# STM32H7R register map
File version: 1.3
CPU: CM7 r0p1, little endian, MPU, FPU, 4 interrupt priority bits
Registers are 32-bit, read-write, reset 0x0 unless marked. A register's access mark holds for its fields unless they carry their own. Offsets are from the block's base; [hi:lo] are bit positions; {n}, {i} and the like mark numbered series; 'fields as' and 'values as' point back to an identical list.

## OTG_HS (part 2 of 3) — OTG register block
Base 0x40040000
Same registers: OTG_FS 0x40080000
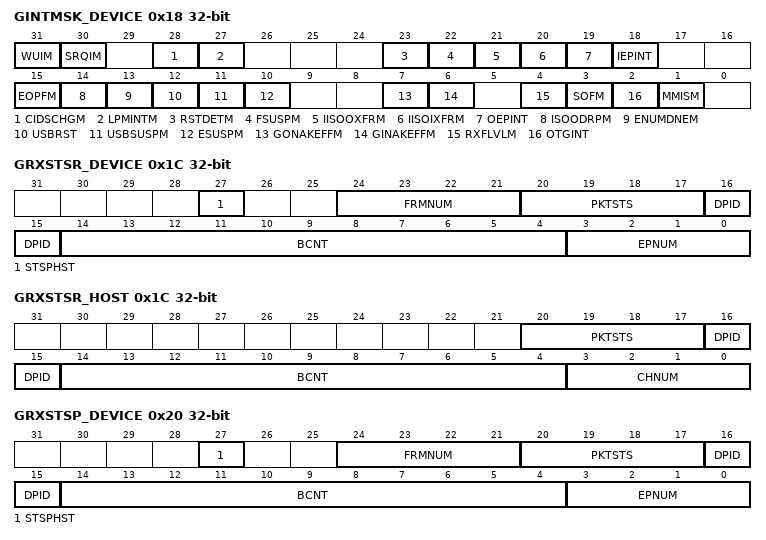
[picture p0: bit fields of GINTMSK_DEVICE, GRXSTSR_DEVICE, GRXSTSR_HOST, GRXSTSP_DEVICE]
0x18 GINTMSK_DEVICE (alternate view of GINTMSK_HOST) — OTG interrupt mask register
  [31] WUIM — Resume/remote wakeup detected interrupt mask
  [30] SRQIM — Session request/new session detected interrupt mask
  [28] CIDSCHGM — Connector ID status change mask
  [27] LPMINTM — LPM interrupt mask
  [23] RSTDETM — Reset detected interrupt mask
  [22] FSUSPM — Data fetch suspended mask
  [21] IISOOXFRM — Incomplete isochronous OUT transfer mask
  [20] IISOIXFRM — Incomplete isochronous IN transfer mask
  [19] OEPINT — OUT endpoints interrupt mask
  [18] IEPINT — IN endpoints interrupt mask
  [15] EOPFM — End of periodic frame interrupt mask
  [14] ISOODRPM — Isochronous OUT packet dropped interrupt mask
  [13] ENUMDNEM — Enumeration done mask
  [12] USBRST — USB reset mask
  [11] USBSUSPM — USB suspend mask
  [10] ESUSPM — Early suspend mask
  [7] GONAKEFFM — Global OUT NAK effective mask
  [6] GINAKEFFM — Global non-periodic IN NAK effective mask
  [4] RXFLVLM — Receive FIFO non-empty mask
  [3] SOFM — Start of frame mask
  [2] OTGINT — OTG interrupt mask
  [1] MMISM — Mode mismatch interrupt mask
0x1C GRXSTSR_DEVICE ro — OTG receive status debug read register
  [27] STSPHST — Status phase start Indicates the start of the status phase for a control write transfer. This bit is set along with the OUT transfer completed PKTSTS pattern.
  [24:21] FRMNUM — Frame number This is the least significant 4 bits of the frame number in which the packet is received on the USB. This field is supported only when isochronous OUT endpoints are supported.
  [20:17] PKTSTS — Packet status Indicates the status of the received packet Others: Reserved
  [16:15] DPID — Data PID Indicates the data PID of the received OUT data packet
  [14:4] BCNT — Byte count Indicates the byte count of the received data packet.
  [3:0] EPNUM — Endpoint number Indicates the endpoint number to which the current received packet belongs.
0x1C GRXSTSR_HOST ro (alternate view of GRXSTSR_DEVICE) — OTG receive status debug read register
  [20:17] PKTSTS — Packet status Indicates the status of the received packet Others: Reserved
  [16:15] DPID — Data PID Indicates the data PID of the received packet
  [14:4] BCNT — Byte count Indicates the byte count of the received IN data packet.
  [3:0] CHNUM — Channel number Indicates the channel number to which the current received packet belongs.
0x20 GRXSTSP_DEVICE ro — OTG status read and pop registers
  fields as GRXSTSR_DEVICE
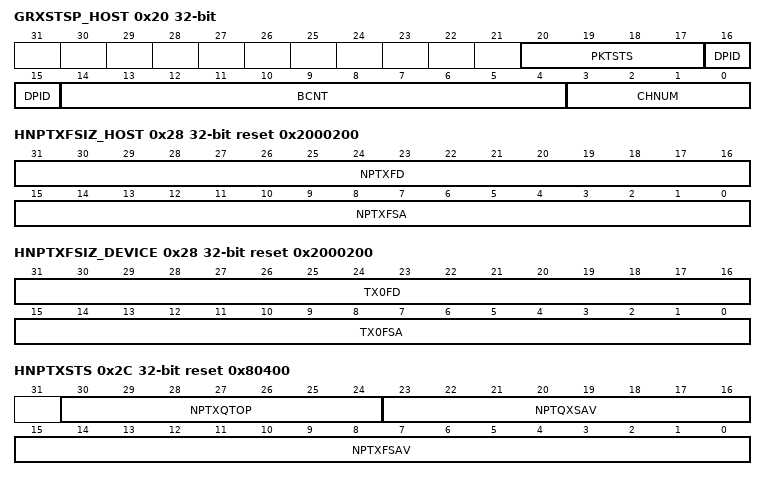
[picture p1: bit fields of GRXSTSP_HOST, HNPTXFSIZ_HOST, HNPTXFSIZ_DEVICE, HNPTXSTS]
0x20 GRXSTSP_HOST ro (alternate view of GRXSTSP_DEVICE) — OTG status read and pop registers
  fields as GRXSTSR_HOST
0x24 GRXFSIZ reset 0x400 — OTG receive FIFO size register
  [15:0] RXFD — Rx FIFO depth This value is in terms of 32-bit words. Maximum value is 1024 Programmed values must respect the available FIFO memory allocation and must not exceed the power-on value.
0x28 HNPTXFSIZ_HOST reset 0x2000200 — OTG host non-periodic transmit FIFO size register [alternate]
  [31:16] NPTXFD — Non-periodic Tx FIFO depth This value is in terms of 32-bit words. Minimum value is 16 Programmed values must respect the available FIFO memory allocation and must not exceed the power-on value.
  [15:0] NPTXFSA — Non-periodic transmit RAM start address This field configures the memory start address for non-periodic transmit FIFO RAM.
0x28 HNPTXFSIZ_DEVICE reset 0x2000200 (alternate view of HNPTXFSIZ_HOST) — OTG host non-periodic transmit FIFO size register [alternate]
  [31:16] TX0FD — Endpoint 0 Tx FIFO depth This value is in terms of 32-bit words. Minimum value is 16 Programmed values must respect the available FIFO memory allocation and must not exceed the power-on value.
  [15:0] TX0FSA — Endpoint 0 transmit RAM start address This field configures the memory start address for the endpoint 0 transmit FIFO RAM.
0x2C HNPTXSTS ro reset 0x80400 — OTG non-periodic transmit FIFO/queue status register
  [30:24] NPTXQTOP — Top of the non-periodic transmit request queue Entry in the non-periodic Tx request queue that is currently being processed by the MAC. Bits 30:27: Channel/endpoint number Bits 26:25: XXXX00X: IN/OUT token XXXX01X: Zero-length transmit packet (device IN/host OUT) XXXX11X: Channel halt command Bit 24: Terminate (last entry for selected channel/endpoint)
  [23:16] NPTQXSAV — Non-periodic transmit request queue space available Indicates the amount of free space available in the non-periodic transmit request queue. This queue holds both IN and OUT requests. n: n locations available (0 UNDER OR EQUAL n UNDER OR EQUAL 8) Others: Reserved
  [15:0] NPTXFSAV — Non-periodic Tx FIFO space available Indicates the amount of free space available in the non-periodic Tx FIFO. Values are in terms of 32-bit words. n: n words available (where 0 UNDER OR EQUAL n UNDER OR EQUAL 512) Others: Reserved
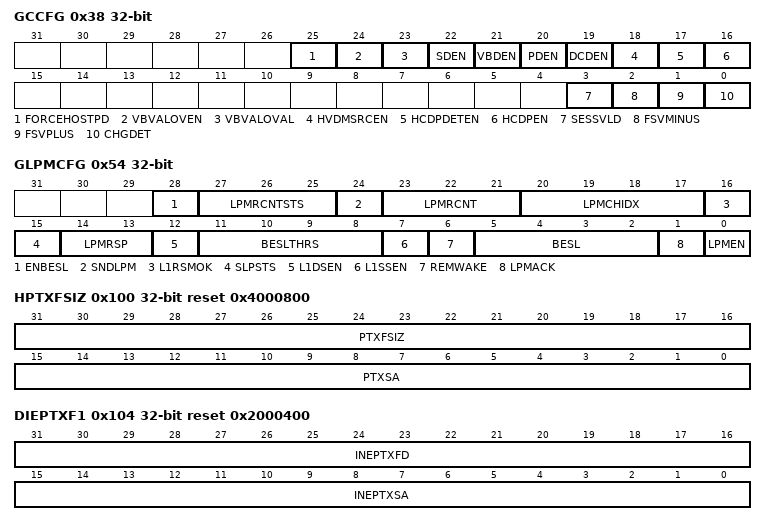
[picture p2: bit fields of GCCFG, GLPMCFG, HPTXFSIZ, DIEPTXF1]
0x38 GCCFG access per field (reset mask 0xFFFF0000) — OTG general core configuration register
  [25] FORCEHOSTPD rw — Force host mode pull-downs If the ID pin functions are enabled, the host mode pull-downs on DP and DM activate automatically. However, whenever that is not the case, yet host mode is required, this bit must be used to force the pull-downs active.
  [24] VBVALOVEN rw — Enables a software override of the VBUS B-session detection.
  [23] VBVALOVAL rw — Software override value of the VBUS B-session detection
  [22] SDEN rw — Secondary detection enable
  [21] VBDEN rw — VBUS detection enable Enables VBUS Sensing Comparators in order to detect VBUS presence and/or perform OTG operation.
  [20] PDEN rw — Primary detection enable
  [19] DCDEN rw — Data Contact Detection enable
  [18] HVDMSRCEN rw — Host CDP port Voltage source enable on DM
  [17] HCDPDETEN rw — Host CDP port voltage detector enable on DP
  [16] HCDPEN rw — Host CDP behavior enable
  [3] SESSVLD ro — VBUS session indicator Indicates if VBUS is above VBUS session threshold.
  [2] FSVMINUS ro — Single-Ended DM indicator This bit gives the voltage level on DM (also result of the comparison with V<sub>LGC</sub> threshold as defined in BC v1.2 standard).
  [1] FSVPLUS ro — Single-Ended DP indicator This bit gives the voltage level on DP (also result of the comparison with V<sub>LGC</sub> threshold as defined in BC v1.2 standard).
  [0] CHGDET ro — Charger detection, result of the current mode (primary or secondary).
0x3C CID reset 0x5000 — OTG core ID register
  [31:0] PRODUCT_ID — Product ID field Application-programmable ID field.
0x54 GLPMCFG access per field — OTG core LPM configuration register
  [28] ENBESL rw — Enable best effort service latency This bit enables the BESL feature as defined in the LPM errata: USB 2.0 Link Power Management Addendum Engineering Change Notice to the USB 2.0 specification, July 16, 2007 Errata for USB 2.0 ECN: Link Power Management (LPM) - 7/2007 Note: Only the updated behavior (described in LPM Errata) is considered in this document and so the ENBESL bit should be set to '1' by application SW.
  [27:25] LPMRCNTSTS ro — LPM retry count status Number of LPM host retries still remaining to be transmitted for the current LPM sequence. Note: Accessible only in host mode.
  [24] SNDLPM rw — Send LPM transaction When the application software sets this bit, an LPM transaction containing two tokens, EXT and LPM is sent. The hardware clears this bit once a valid response (STALL, NYET, or ACK) is received from the device or the core has finished transmitting the programmed number of LPM retries. Note: This bit must be set only when the host is connected to a local port. Note: Accessible only in host mode.
  [23:21] LPMRCNT rw — LPM retry count When the device gives an ERROR response, this is the number of additional LPM retries that the host performs until a valid device response (STALL, NYET, or ACK) is received. Note: Accessible only in host mode.
  [20:17] LPMCHIDX rw — LPM Channel Index The channel number on which the LPM transaction has to be applied while sending an LPM transaction to the local device. Based on the LPM channel index, the core automatically inserts the device address and endpoint number programmed in the corresponding channel into the LPM transaction. Note: Accessible only in host mode.
  [16] L1RSMOK ro — Sleep state resume OK
  [15] SLPSTS ro — Port sleep status Device mode: This bit is set as long as a Sleep condition is present on the USB bus. The core enters the Sleep state when an ACK response is sent to an LPM transaction and the T<sub>L1TokenRetry</sub> timer has expired. To stop the PHY clock, the application must set the STPPCLK bit in OTG_PCGCCTL, which asserts the PHY suspend input signal. The application must rely on SLPSTS and not ACK in LPMRSP to confirm transition into sleep. The core comes out of sleep: When there is any activity on the USB linestate When the application writes to the RWUSIG bit in OTG_DCTL or when the application resets or soft-disconnects the device. Host mode: The host transitions to Sleep (L1) state as a side-effect of a successful LPM transaction by the core to the local port with ACK response from the device. The read value of this bit reflects the current Sleep status of the port. The core clears this bit after: The core detects a remote L1 wakeup signal, The application sets the PRST bit or the PRES bit in the OTG_HPRT register, or The application sets the L1Resume/ remote wakeup detected interrupt bit or disconnect detected interrupt bit in the core interrupt register (WKUPINT or DISCINT bit in OTG_GINTSTS, respectively).
  [14:13] LPMRSP ro — LPM response Device mode: The response of the core to LPM transaction received is reflected in these two bits. Host mode: Handshake response received from local device for LPM transaction
  [12] L1DSEN rw — L1 deep sleep enable Enables suspending the PHY in L1 Sleep mode. For maximum power saving during L1 Sleep mode, this bit should be set to '1' by application SW in all the cases.
  [11:8] BESLTHRS rw — BESL threshold Device mode
  [7] L1SSEN rw — L1 Shallow Sleep enable Enables suspending the PHY in L1 Sleep mode. For maximum power saving during L1 Sleep mode, this bit should be set to '1' by application SW in all the cases.
  [6] REMWAKE rw — bRemoteWake value Host mode: The value of remote wake up to be sent in the wIndex field of LPM transaction. Device mode (read-only): This field is updated with the received LPM token bRemoteWake bmAttribute when an ACK, NYET, or STALL response is sent to an LPM transaction.
  [5:2] BESL rw — Best effort service latency Host mode
  [1] LPMACK rw — LPM token acknowledge enable Handshake response to LPM token preprogrammed by device application software. Even though ACK is preprogrammed, the core device responds with ACK only on successful LPM transaction. The LPM transaction is successful if: No PID/CRC5 errors in either EXT token or LPM token (else ERROR) Valid bLinkState = 0001B (L1) received in LPM transaction (else STALL) No data pending in transmit queue (else NYET). The preprogrammed software bit is over-ridden for response to LPM token when: The received bLinkState is not L1 (STALL response), or An error is detected in either of the LPM token packets because of corruption (ERROR response). Note: Accessible only in device mode.
  [0] LPMEN rw — LPM support enable The application uses this bit to control the OTG_HS core LPM capabilities. If the core operates as a non-LPM-capable host, it cannot request the connected device or hub to activate LPM mode. If the core operates as a non-LPM-capable device, it cannot respond to any LPM transactions.
0x100 HPTXFSIZ reset 0x4000800 — OTG host periodic transmit FIFO size register
  [31:16] PTXFSIZ — Host periodic Tx FIFO depth This value is in terms of 32-bit words. Minimum value is 16
  [15:0] PTXSA — Host periodic Tx FIFO start address This field configures the memory start address for periodic transmit FIFO RAM.
0x104 DIEPTXF1 reset 0x2000400 — OTG device IN endpoint transmit FIFO 1 size register
  [31:16] INEPTXFD — IN endpoint Tx FIFO depth This value is in terms of 32-bit words. Minimum value is 16
  [15:0] INEPTXSA — IN endpoint FIFOx transmit RAM start address This field contains the memory start address for IN endpoint transmit FIFOx. The address must be aligned with a 32-bit memory location.
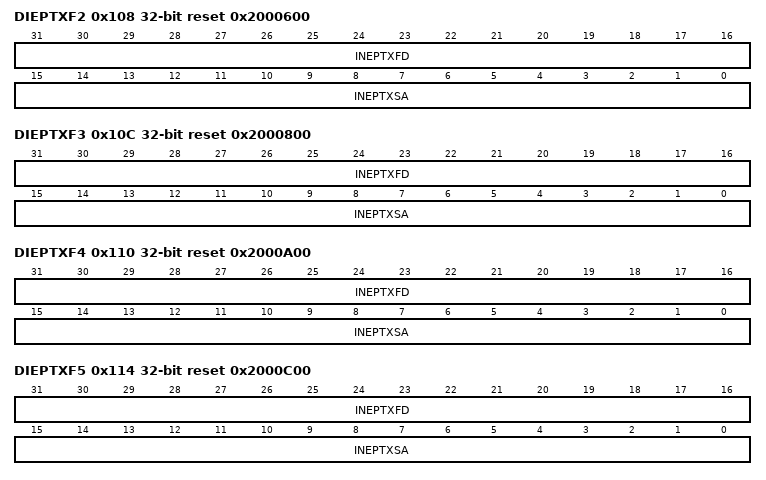
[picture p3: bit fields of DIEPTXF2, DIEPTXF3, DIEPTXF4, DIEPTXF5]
0x108 DIEPTXF2 reset 0x2000600 — OTG device IN endpoint transmit FIFO 2 size register
  fields as DIEPTXF1
0x10C DIEPTXF3 reset 0x2000800 — OTG device IN endpoint transmit FIFO 3 size register
  fields as DIEPTXF1
0x110 DIEPTXF4 reset 0x2000A00 — OTG device IN endpoint transmit FIFO 4 size register
  fields as DIEPTXF1
0x114 DIEPTXF5 reset 0x2000C00 — OTG device IN endpoint transmit FIFO 5 size register
  fields as DIEPTXF1
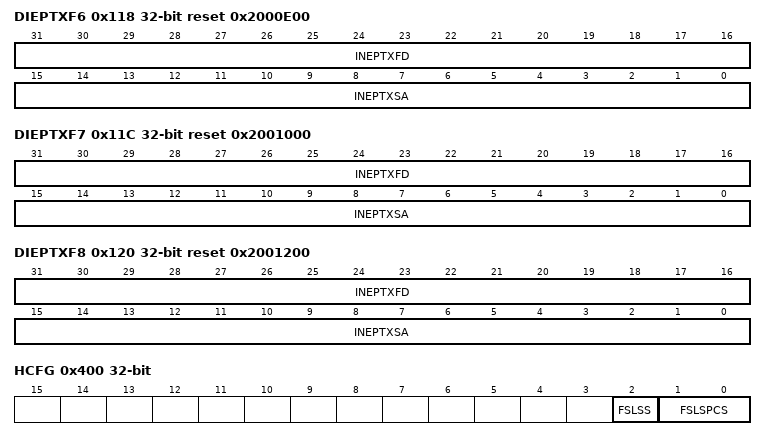
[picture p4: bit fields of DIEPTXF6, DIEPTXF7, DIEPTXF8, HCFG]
0x118 DIEPTXF6 reset 0x2000E00 — OTG device IN endpoint transmit FIFO 6 size register
  fields as DIEPTXF1
0x11C DIEPTXF7 reset 0x2001000 — OTG device IN endpoint transmit FIFO 7 size register
  fields as DIEPTXF1
0x120 DIEPTXF8 reset 0x2001200 — OTG device IN endpoint transmit FIFO 8 size register
  fields as DIEPTXF1
0x400 HCFG access per field — OTG host configuration register
  [2] FSLSS ro — FS- and LS-only support The application uses this bit to control the cores enumeration speed. Using this bit, the application can make the core enumerate as an FS host, even if the connected device supports HS traffic. Do not make changes to this field after initial programming.
  [1:0] FSLSPCS rw — FS/LS PHY clock select Others: Reserved Note: The FSLSPCS must be set on a connection event according to the speed of the connected device (after changing this bit, a software reset must be performed).
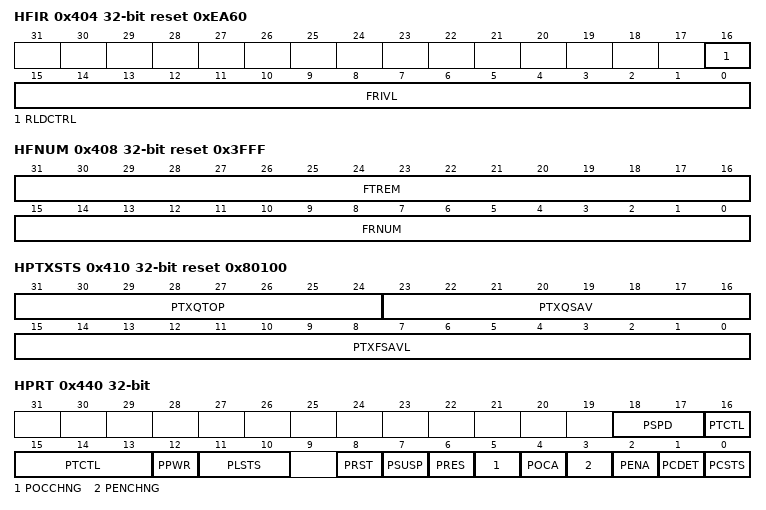
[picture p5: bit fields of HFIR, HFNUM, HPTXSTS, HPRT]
0x404 HFIR reset 0xEA60 — OTG host frame interval register
  [16] RLDCTRL — Reload control This bit allows dynamic reloading of the HFIR register during run time. This bit needs to be programmed during initial configuration and its value must not be changed during run time. RLDCTRL = 0 is not recommended.
  [15:0] FRIVL — Frame interval
0x408 HFNUM ro reset 0x3FFF — OTG host frame number/frame time remaining register
  [31:16] FTREM — Frame time remaining Indicates the amount of time remaining in the current frame, in terms of PHY clocks. This field decrements on each PHY clock. When it reaches zero, this field is reloaded with the value in the Frame interval register and a new SOF is transmitted on the USB.
  [15:0] FRNUM — Frame number This field increments when a new SOF is transmitted on the USB, and is cleared to 0 when it reaches 0x3FFF.
0x410 HPTXSTS ro reset 0x80100 — OTG_Host periodic transmit FIFO/queue status register
  [31:24] PTXQTOP — Top of the periodic transmit request queue This indicates the entry in the periodic Tx request queue that is currently being processed by the MAC. This register is used for debugging. Bit 31: Odd/Even frame 0XXXXXXX: send in even frame 1XXXXXXX: send in odd frame Bits 30:27: Channel/endpoint number Bits 26:25: Type XXXXX00X: IN/OUT XXXXX01X: Zero-length packet XXXXX11X: Disable channel command Bit 24: Terminate (last entry for the selected channel/endpoint)
  [23:16] PTXQSAV — Periodic transmit request queue space available Indicates the number of free locations available to be written in the periodic transmit request queue. This queue holds both IN and OUT requests. n: n locations available (0 UNDER OR EQUAL n UNDER OR EQUAL 8) Others: Reserved
  [15:0] PTXFSAVL — Periodic transmit data FIFO space available Indicates the number of free locations available to be written to in the periodic Tx FIFO. Values are in terms of 32-bit words n: n words available (where 0 UNDER OR EQUAL n UNDER OR EQUAL PTXFD) Others: Reserved
0x414 HAINT ro — OTG host all channels interrupt register
  [15:0] HAINT — Channel interrupts One bit per channel: Bit 0 for Channel 0, bit 15 for Channel 15
0x418 HAINTMSK — OTG host all channels interrupt mask register
  [15:0] HAINTM — Channel interrupt mask One bit per channel: Bit 0 for channel 0, bit 15 for channel 15
0x440 HPRT access per field — OTG host port control and status register
  [18:17] PSPD ro — Port speed Indicates the speed of the device attached to this port.
  [16:13] PTCTL rw — Port test control The application writes a nonzero value to this field to put the port into a Test mode, and the corresponding pattern is signaled on the port. Others: Reserved
  [12] PPWR rw — Port power The application uses this field to control power to this port, and the core clears this bit on an overcurrent condition.
  [11:10] PLSTS ro — Port line status Indicates the current logic level USB data lines Bit 10: Logic level of OTG_DP Bit 11: Logic level of OTG_DM
  [8] PRST rw — Port reset When the application sets this bit, a reset sequence is started on this port. The application must time the reset period and clear this bit after the reset sequence is complete. The application must leave this bit set for a minimum duration of at least 10 ms to start a reset on the port. The application can leave it set for another 10 ms in addition to the required minimum duration, before clearing the bit, even though there is no maximum limit set by the USB standard. High speed: 50 ms Full speed/Low speed: 10 ms
  [7] PSUSP rw — Port suspend The application sets this bit to put this port in suspend mode. The core only stops sending SOFs when this is set. To stop the PHY clock, the application must set the port clock stop bit, which asserts the suspend input pin of the PHY. The read value of this bit reflects the current suspend status of the port. This bit is cleared by the core after a remote wakeup signal is detected or the application sets the port reset bit or port resume bit in this register or the resume/remote wakeup detected interrupt bit or disconnect detected interrupt bit in the core interrupt register (WKUPINT or DISCINT in OTG_GINTSTS, respectively).
  [6] PRES rw — Port resume The application sets this bit to drive resume signaling on the port. The core continues to drive the resume signal until the application clears this bit. If the core detects a USB remote wakeup sequence, as indicated by the port resume/remote wakeup detected interrupt bit of the core interrupt register (WKUPINT bit in OTG_GINTSTS), the core starts driving resume signaling without application intervention and clears this bit when it detects a disconnect condition. The read value of this bit indicates whether the core is currently driving resume signaling. When LPM is enabled and the core is in L1 state, the behavior of this bit is as follow: 1. The application sets this bit to drive resume signaling on the port. 2. The core continues to drive the resume signal until a predetermined time specified in BESLTHRS[3:0] field of OTG_GLPMCFG register. 3. If the core detects a USB remote wakeup sequence, as indicated by the port L1Resume/Remote L1Wakeup detected interrupt bit of the core interrupt register (WKUPINT in OTG_GINTSTS), the core starts driving resume signaling without application intervention and clears this bit at the end of resume.This bit can be set or cleared by both the core and the application. This bit is cleared by the core even if there is no device connected to the host.
  [5] POCCHNG rw — Port overcurrent change The core sets this bit when the status of the port overcurrent active bit (bit 4) in this register changes.
  [4] POCA ro — Port overcurrent active Indicates the overcurrent condition of the port.
  [3] PENCHNG rw — Port enable/disable change The core sets this bit when the status of the port enable bit 2 in this register changes.
  [2] PENA rw — Port enable A port is enabled only by the core after a reset sequence, and is disabled by an overcurrent condition, a disconnect condition, or by the application clearing this bit. The application cannot set this bit by a register write. It can only clear it to disable the port. This bit does not trigger any interrupt to the application.
  [1] PCDET rw — Port connect detected The core sets this bit when a device connection is detected to trigger an interrupt to the application using the host port interrupt bit in the core interrupt register (HPRTINT bit in OTG_GINTSTS). The application must write a 1 to this bit to clear the interrupt.
  [0] PCSTS ro — Port connect status
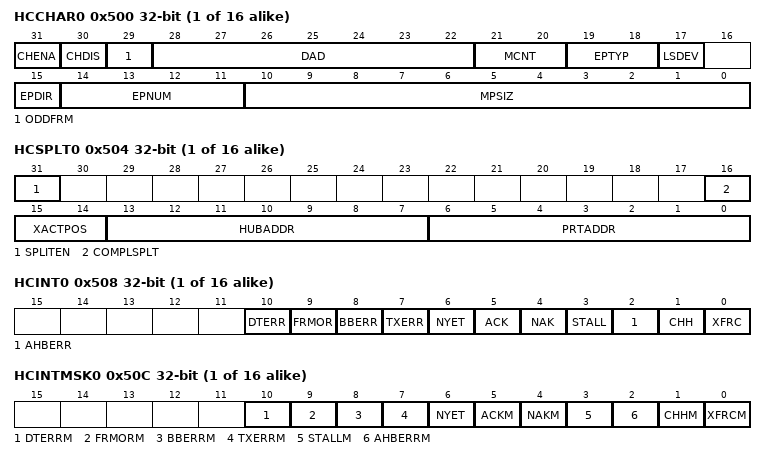
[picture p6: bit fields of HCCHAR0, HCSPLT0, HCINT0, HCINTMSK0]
{0x500+0x20*i} HCCHAR{i} (i=0..15) — OTG host channel {i} characteristics register
  [31] CHENA — Channel enable This field is set by the application and cleared by the OTG host.
  [30] CHDIS — Channel disable The application sets this bit to stop transmitting/receiving data on a channel, even before the transfer for that channel is complete. The application must wait for the Channel disabled interrupt before treating the channel as disabled.
  [29] ODDFRM — Odd frame This field is set (reset) by the application to indicate that the OTG host must perform a transfer in an odd frame. This field is applicable for only periodic (isochronous and interrupt) transactions.
  [28:22] DAD — Device address This field selects the specific device serving as the data source or sink.
  [21:20] MCNT — Multicount This field indicates to the host the number of transactions that must be executed per frame for this periodic endpoint. For non-periodic transfers, this field is not used Note: This field must be set to at least 01.
  [19:18] EPTYP — Endpoint type Indicates the transfer type selected.
  [17] LSDEV — Low-speed device This field is set by the application to indicate that this channel is communicating to a low-speed device.
  [15] EPDIR — Endpoint direction Indicates whether the transaction is IN or OUT.
  [14:11] EPNUM — Endpoint number Indicates the endpoint number on the device serving as the data source or sink.
  [10:0] MPSIZ — Maximum packet size Indicates the maximum packet size of the associated endpoint.
{0x504+0x20*i} HCSPLT{i} (i=0..15) — OTG host channel {i} split control register
  [31] SPLITEN — Split enable The application sets this bit to indicate that this channel is enabled to perform split transactions.
  [16] COMPLSPLT — Do complete split The application sets this bit to request the OTG host to perform a complete split transaction.
  [15:14] XACTPOS — Transaction position This field is used to determine whether to send all, first, middle, or last payloads with each OUT transaction.
  [13:7] HUBADDR — Hub address This field holds the device address of the transaction translators hub.
  [6:0] PRTADDR — Port address This field is the port number of the recipient transaction translator.
{0x508+0x20*i} HCINT{i} (i=0..15) — OTG host channel {i} interrupt register
  [10] DTERR — Data toggle error.
  [9] FRMOR — Frame overrun.
  [8] BBERR — Babble error.
  [7] TXERR — Transaction error. Indicates one of the following errors occurred on the USB. CRC check failure Timeout Bit stuff error False EOP
  [6] NYET — Not yet ready response received interrupt.
  [5] ACK — ACK response received/transmitted interrupt.
  [4] NAK — NAK response received interrupt.
  [3] STALL — STALL response received interrupt.
  [2] AHBERR — AHB error This error is generated only in Internal DMA mode when an AHB error occurs during an AHB read/write operation. The application can read the corresponding DMA channel address register to get the error address.
  [1] CHH — Channel halted. Indicates the transfer completed abnormally either because of any USB transaction error or in response to disable request by the application.
  [0] XFRC — Transfer completed. Transfer completed normally without any errors.
{0x50C+0x20*i} HCINTMSK{i} (i=0..15) — OTG host channel {i} interrupt mask register
  [10] DTERRM — Data toggle error mask.
  [9] FRMORM — Frame overrun mask.
  [8] BBERRM — Babble error mask.
  [7] TXERRM — Transaction error mask.
  [6] NYET — response received interrupt mask.
  [5] ACKM — ACK response received/transmitted interrupt mask.
  [4] NAKM — NAK response received interrupt mask.
  [3] STALLM — STALL response received interrupt mask.
  [2] AHBERRM — AHB error.
  [1] CHHM — Channel halted mask
  [0] XFRCM — Transfer completed mask
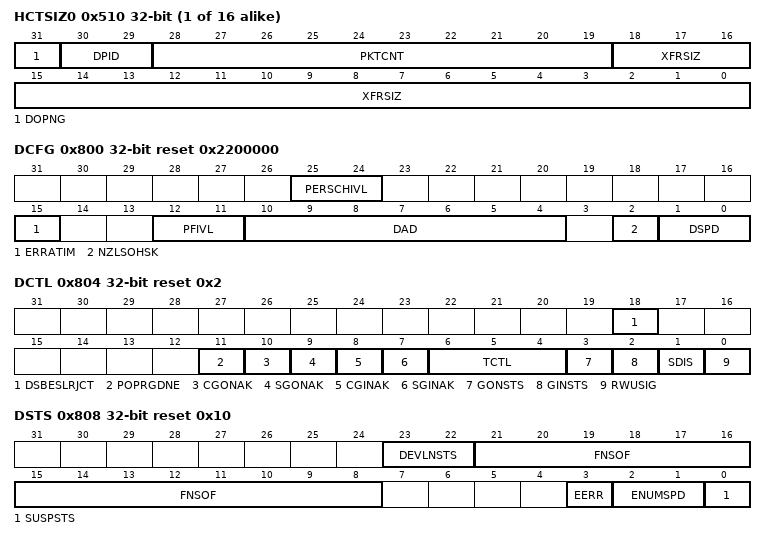
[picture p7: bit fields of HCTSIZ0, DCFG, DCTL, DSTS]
{0x510+0x20*i} HCTSIZ{i} (i=0..15) — OTG host channel {i} transfer size register
  [31] DOPNG — Do Ping This bit is used only for OUT transfers. Setting this field to 1 directs the host to do PING protocol. Note: Do not set this bit for IN transfers. If this bit is set for IN transfers, it disables the channel.
  [30:29] DPID — Data PID The application programs this field with the type of PID to use for the initial transaction. The host maintains this field for the rest of the transfer.
  [28:19] PKTCNT — Packet count This field is programmed by the application with the expected number of packets to be transmitted (OUT) or received (IN). The host decrements this count on every successful transmission or reception of an OUT/IN packet. Once this count reaches zero, the application is interrupted to indicate normal completion.
  [18:0] XFRSIZ — Transfer size For an OUT, this field is the number of data bytes the host sends during the transfer. For an IN, this field is the buffer size that the application has reserved for the transfer. The application is expected to program this field as an integer multiple of the maximum packet size for IN transactions (periodic and non-periodic).
{0x514+0x20*i} HCDMA{i} (i=0..15) — OTG host channel {i} DMA address register
  [31:0] DMAADDR — DMA address This field holds the start address in the external memory from which the data for the endpoint must be fetched or to which it must be stored. This register is incremented on every AHB transaction.
0x800 DCFG reset 0x2200000 — OTG device configuration register
  [25:24] PERSCHIVL — Periodic schedule interval This field specifies the amount of time the Internal DMA engine must allocate for fetching periodic IN endpoint data. Based on the number of periodic endpoints, this value must be specified as 25, 50 or 75% of the (micro) frame. When any periodic endpoints are active, the internal DMA engine allocates the specified amount of time in fetching periodic IN endpoint data When no periodic endpoint is active, then the internal DMA engine services nonperiodic endpoints, ignoring this field After the specified time within a (micro) frame, the DMA switches to fetching nonperiodic endpoints
  [15] ERRATIM — Erratic error interrupt mask
  [12:11] PFIVL — Periodic frame interval Indicates the time within a frame at which the application must be notified using the end of periodic frame interrupt. This can be used to determine if all the isochronous traffic for that frame is complete.
  [10:4] DAD — Device address The application must program this field after every SetAddress control command.
  [2] NZLSOHSK — Non-zero-length status OUT handshake The application can use this field to select the handshake the core sends on receiving a nonzero-length data packet during the OUT transaction of a control transfers status stage.
  [1:0] DSPD — Device speed Indicates the speed at which the application requires the core to enumerate, or the maximum speed the application can support. However, the actual bus speed is determined only after the chirp sequence is completed, and is based on the speed of the USB host to which the core is connected.
0x804 DCTL access per field reset 0x2 — OTG device control register
  [18] DSBESLRJCT rw — Deep sleep BESL reject Core rejects LPM request with BESL value greater than BESL threshold programmed. NYET response is sent for LPM tokens with BESL value greater than BESL threshold. By default, the deep sleep BESL reject feature is disabled.
  [11] POPRGDNE rw — Power-on programming done The application uses this bit to indicate that register programming is completed after a wakeup from power down mode.
  [10] CGONAK wo — Clear global OUT NAK Writing 1 to this field clears the Global OUT NAK.
  [9] SGONAK wo — Set global OUT NAK Writing 1 to this field sets the Global OUT NAK. The application uses this bit to send a NAK handshake on all OUT endpoints. The application must set the this bit only after making sure that the Global OUT NAK effective bit in the core interrupt register (GONAKEFF bit in OTG_GINTSTS) is cleared.
  [8] CGINAK wo — Clear global IN NAK Writing 1 to this field clears the Global IN NAK.
  [7] SGINAK wo — Set global IN NAK Writing 1 to this field sets the Global non-periodic IN NAK.The application uses this bit to send a NAK handshake on all non-periodic IN endpoints. The application must set this bit only after making sure that the Global IN NAK effective bit in the core interrupt register (GINAKEFF bit in OTG_GINTSTS) is cleared.
  [6:4] TCTL rw — Test control Others: Reserved
  [3] GONSTS ro — Global OUT NAK status
  [2] GINSTS ro — Global IN NAK status
  [1] SDIS rw — Soft disconnect The application uses this bit to signal the USB OTG core to perform a soft disconnect. As long as this bit is set, the host does not see that the device is connected, and the device does not receive signals on the USB. The core stays in the disconnected state until the application clears this bit.
  [0] RWUSIG rw — Remote wakeup signaling When the application sets this bit, the core initiates remote signaling to wake up the USB host. The application must set this bit to instruct the core to exit the suspend state. As specified in the USB 2.0 specification, the application must clear this bit 1 ms to 15 ms after setting it. If LPM is enabled and the core is in the L1 (sleep) state, when the application sets this bit, the core initiates L1 remote signaling to wake up the USB host. The application must set this bit to instruct the core to exit the sleep state. As specified in the LPM specification, the hardware automatically clears this bit 50 s (T<sub>L1DevDrvResume</sub>) after being set by the application. The application must not set this bit when bRemoteWake from the previous LPM transaction is zero (refer to REMWAKE bit in GLPMCFG register).
0x808 DSTS ro reset 0x10 — OTG device status register
  [23:22] DEVLNSTS — Device line status Indicates the current logic level USB data lines. Bit [23]: Logic level of D+ Bit [22]: Logic level of D-
  [21:8] FNSOF — Frame number of the received SOF
  [3] EERR — Erratic error The core sets this bit to report any erratic errors. Due to erratic errors, the OTG_HS controller goes into suspended state and an interrupt is generated to the application with Early suspend bit of the OTG_GINTSTS register (ESUSP bit in OTG_GINTSTS). If the early suspend is asserted due to an erratic error, the application can only perform a soft disconnect recover.
  [2:1] ENUMSPD — Enumerated speed Indicates the speed at which the OTG_HS controller has come up after speed detection through a chirp sequence. Others: reserved
  [0] SUSPSTS — Suspend status In device mode, this bit is set as long as a suspend condition is detected on the USB. The core enters the suspended state when there is no activity on the USB data lines for a period of 3 ms. The core comes out of the suspend: When there is an activity on the USB data lines When the application writes to the remote wakeup signaling bit in the OTG_DCTL register (RWUSIG bit in OTG_DCTL).
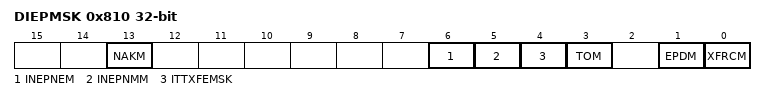
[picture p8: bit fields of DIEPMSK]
0x810 DIEPMSK — OTG device IN endpoint common interrupt mask register
  [13] NAKM — NAK interrupt mask
  [6] INEPNEM — IN endpoint NAK effective mask
  [5] INEPNMM — IN token received with EP mismatch mask
  [4] ITTXFEMSK — IN token received when Tx FIFO empty mask
  [3] TOM — Timeout condition mask (Non-isochronous endpoints)
  [1] EPDM — Endpoint disabled interrupt mask
  [0] XFRCM — Transfer completed interrupt mask
